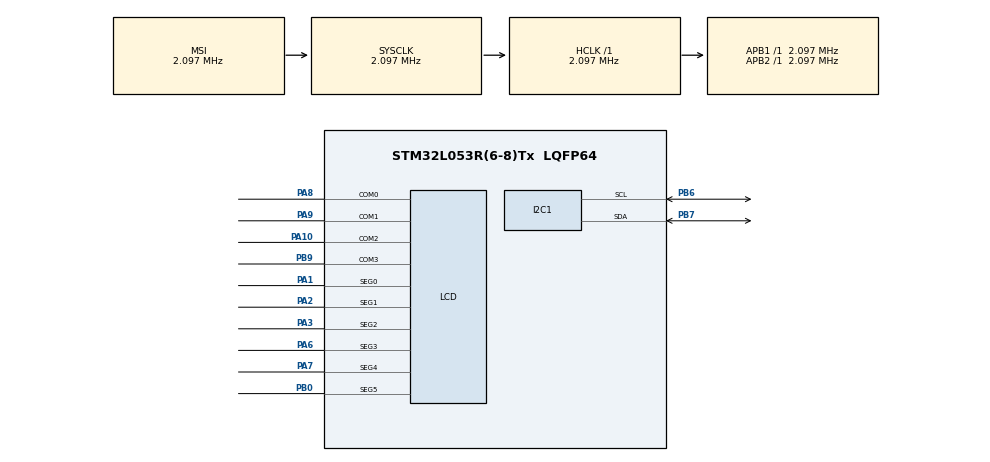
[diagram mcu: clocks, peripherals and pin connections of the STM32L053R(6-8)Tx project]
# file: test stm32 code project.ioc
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I2C1.Timing=0x00000608
Mcu.Family=STM32L0
Mcu.Name=STM32L053R(6-8)Tx
Mcu.Package=LQFP64
PA1.Mode=SEG0
PA1.Signal=LCD_SEG0
PA10.Mode=1/4 Duty Cycle
PA10.Signal=LCD_COM2
PA13.Mode=Serial_Wire
PA13.Signal=SYS_SWDIO
PA14.Mode=Serial_Wire
PA14.Signal=SYS_SWCLK
PA2.Mode=SEG1
PA2.Signal=LCD_SEG1
PA3.Mode=SEG2
PA3.Signal=LCD_SEG2
PA6.Mode=SEG3
PA6.Signal=LCD_SEG3
PA7.Mode=SEG4
PA7.Signal=LCD_SEG4
PA8.Mode=1/4 Duty Cycle
PA8.Signal=LCD_COM0
PA9.Mode=1/4 Duty Cycle
PA9.Signal=LCD_COM1
PB0.Mode=SEG5
PB0.Signal=LCD_SEG5
PB6.Mode=I2C
PB6.Signal=I2C1_SCL
PB7.Mode=I2C
PB7.Signal=I2C1_SDA
PB9.Mode=1/4 Duty Cycle
PB9.Signal=LCD_COM3
PC14-OSC32_IN.Mode=LSE-External-Oscillator
PC14-OSC32_IN.Signal=RCC_OSC32_IN
PC15-OSC32_OUT.Mode=LSE-External-Oscillator
PC15-OSC32_OUT.Signal=RCC_OSC32_OUT
ProjectManager.HeapSize=0x200
ProjectManager.StackSize=0x400
ProjectManager.TargetToolchain=EWARM V8.32
RCC.AHBFreq_Value=2097000
RCC.APB1Freq_Value=2097000
RCC.APB1TimFreq_Value=2097000
RCC.APB2Freq_Value=2097000
RCC.APB2TimFreq_Value=2097000
RCC.HSE_VALUE=8000000
RCC.HSI16_VALUE=16000000
RCC.HSI48_VALUE=48000000
RCC.HSI_VALUE=16000000
RCC.MSI_VALUE=2097000
RCC.RTCClockSelection=RCC_RTCCLKSOURCE_LSE
RCC.RTCClockSelectionVirtual=RCC_RTCCLKSOURCE_LSE
RCC.SYSCLKFreq_VALUE=2097000
RCC.VCOOutputFreq_Value=48000000
VP_LCD_LCD_Bias.Mode=1/2 Bias
board=custom

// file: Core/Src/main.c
/* USER CODE BEGIN Header */
/**
  ******************************************************************************
  * @file           : main.c
  * @brief          : Main program body
  ******************************************************************************
  * @attention
  *
  * Copyright (c) 2026 STMicroelectronics.
  * All rights reserved.
  *
  * This software is licensed under terms that can be found in the LICENSE file
  * in the root directory of this software component.
  * If no LICENSE file comes with this software, it is provided AS-IS.
  *
  ******************************************************************************
  */
/* USER CODE END Header */
#include "main.h"

I2C_HandleTypeDef hi2c1;

LCD_HandleTypeDef hlcd;

void SystemClock_Config(void);
static void MX_GPIO_Init(void);
static void MX_I2C1_Init(void);
static void MX_LCD_Init(void);

int main(void)
{

  /* USER CODE BEGIN 1 */
	HAL_LCD_Clear(&hlcd);
	HAL_LCD_DisplayString(&hlcd, (uint8_t*)"12");
  /* USER CODE END 1 */

  /* MCU Configuration--------------------------------------------------------*/

  /* Reset of all peripherals, Initializes the Flash interface and the Systick. */
  HAL_Init();

  /* Configure the system clock */
  SystemClock_Config();

  /* Initialize all configured peripherals */
  MX_GPIO_Init();
  MX_I2C1_Init();
  MX_LCD_Init();

  /* Infinite loop */
  while (1)
  {

  }
}

void SystemClock_Config(void)
{
  RCC_OscInitTypeDef RCC_OscInitStruct = {0};
  RCC_ClkInitTypeDef RCC_ClkInitStruct = {0};
  RCC_PeriphCLKInitTypeDef PeriphClkInit = {0};

  /** Configure the main internal regulator output voltage
  */
  __HAL_PWR_VOLTAGESCALING_CONFIG(PWR_REGULATOR_VOLTAGE_SCALE1);

  /** Configure LSE Drive Capability
  */
  HAL_PWR_EnableBkUpAccess();
  __HAL_RCC_LSEDRIVE_CONFIG(RCC_LSEDRIVE_LOW);

  /** Initializes the RCC Oscillators according to the specified parameters
  * in the RCC_OscInitTypeDef structure.
  */
  RCC_OscInitStruct.OscillatorType = RCC_OSCILLATORTYPE_LSE|RCC_OSCILLATORTYPE_MSI;
  RCC_OscInitStruct.LSEState = RCC_LSE_ON;
  RCC_OscInitStruct.MSIState = RCC_MSI_ON;
  RCC_OscInitStruct.MSICalibrationValue = 0;
  RCC_OscInitStruct.MSIClockRange = RCC_MSIRANGE_5;
  RCC_OscInitStruct.PLL.PLLState = RCC_PLL_NONE;
  if (HAL_RCC_OscConfig(&RCC_OscInitStruct) != HAL_OK)
  {
    Error_Handler();
  }

  /** Initializes the CPU, AHB and APB buses clocks
  */
  RCC_ClkInitStruct.ClockType = RCC_CLOCKTYPE_HCLK|RCC_CLOCKTYPE_SYSCLK
                              |RCC_CLOCKTYPE_PCLK1|RCC_CLOCKTYPE_PCLK2;
  RCC_ClkInitStruct.SYSCLKSource = RCC_SYSCLKSOURCE_MSI;
  RCC_ClkInitStruct.AHBCLKDivider = RCC_SYSCLK_DIV1;
  RCC_ClkInitStruct.APB1CLKDivider = RCC_HCLK_DIV1;
  RCC_ClkInitStruct.APB2CLKDivider = RCC_HCLK_DIV1;

  if (HAL_RCC_ClockConfig(&RCC_ClkInitStruct, FLASH_LATENCY_0) != HAL_OK)
  {
    Error_Handler();
  }
  PeriphClkInit.PeriphClockSelection = RCC_PERIPHCLK_I2C1|RCC_PERIPHCLK_RTC;
  PeriphClkInit.I2c1ClockSelection = RCC_I2C1CLKSOURCE_PCLK1;
  PeriphClkInit.RTCClockSelection = RCC_RTCCLKSOURCE_LSE;
  if (HAL_RCCEx_PeriphCLKConfig(&PeriphClkInit) != HAL_OK)
  {
    Error_Handler();
  }
}

static void MX_I2C1_Init(void)
{

  hi2c1.Instance = I2C1;
  hi2c1.Init.Timing = 0x00000608;
  hi2c1.Init.OwnAddress1 = 0;
  hi2c1.Init.AddressingMode = I2C_ADDRESSINGMODE_7BIT;
  hi2c1.Init.DualAddressMode = I2C_DUALADDRESS_DISABLE;
  hi2c1.Init.OwnAddress2 = 0;
  hi2c1.Init.OwnAddress2Masks = I2C_OA2_NOMASK;
  hi2c1.Init.GeneralCallMode = I2C_GENERALCALL_DISABLE;
  hi2c1.Init.NoStretchMode = I2C_NOSTRETCH_DISABLE;
  if (HAL_I2C_Init(&hi2c1) != HAL_OK)
  {
    Error_Handler();
  }

  /** Configure Analogue filter
  */
  if (HAL_I2CEx_ConfigAnalogFilter(&hi2c1, I2C_ANALOGFILTER_ENABLE) != HAL_OK)
  {
    Error_Handler();
  }

  /** Configure Digital filter
  */
  if (HAL_I2CEx_ConfigDigitalFilter(&hi2c1, 0) != HAL_OK)
  {
    Error_Handler();
  }

}

static void MX_LCD_Init(void)
{

  hlcd.Instance = LCD;
  hlcd.Init.Prescaler = LCD_PRESCALER_1;
  hlcd.Init.Divider = LCD_DIVIDER_16;
  hlcd.Init.Duty = LCD_DUTY_1_4;
  hlcd.Init.Bias = LCD_BIAS_1_2;
  hlcd.Init.VoltageSource = LCD_VOLTAGESOURCE_INTERNAL;
  hlcd.Init.Contrast = LCD_CONTRASTLEVEL_0;
  hlcd.Init.DeadTime = LCD_DEADTIME_0;
  hlcd.Init.PulseOnDuration = LCD_PULSEONDURATION_0;
  hlcd.Init.HighDrive = LCD_HIGHDRIVE_0;
  hlcd.Init.BlinkMode = LCD_BLINKMODE_OFF;
  hlcd.Init.BlinkFrequency = LCD_BLINKFREQUENCY_DIV8;
  hlcd.Init.MuxSegment = LCD_MUXSEGMENT_DISABLE;
  if (HAL_LCD_Init(&hlcd) != HAL_OK)
  {
    Error_Handler();
  }

}

static void MX_GPIO_Init(void)
{

  /* GPIO Ports Clock Enable */
  __HAL_RCC_GPIOC_CLK_ENABLE();
  __HAL_RCC_GPIOA_CLK_ENABLE();
  __HAL_RCC_GPIOB_CLK_ENABLE();

}

void Error_Handler(void)
{
  __disable_irq();
  while (1)
  {
  }
}
